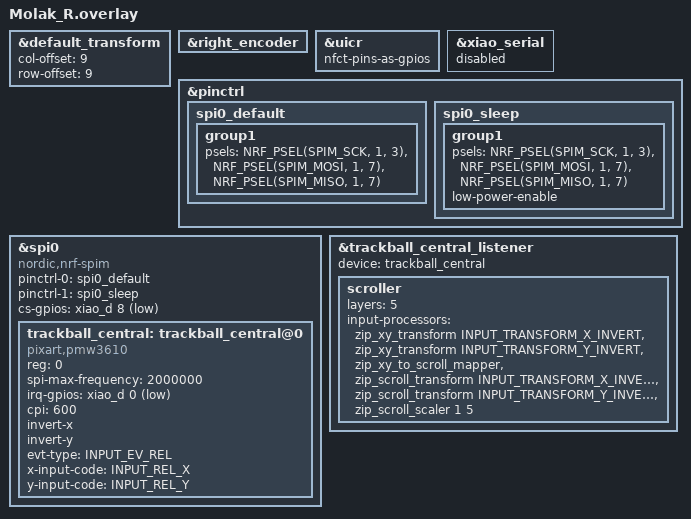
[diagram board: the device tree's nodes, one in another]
#include "Molak.dtsi"
#include <input/processors.dtsi>
#include <zephyr/dt-bindings/input/input-event-codes.h>

&default_transform {
    col-offset = <9>;
    row-offset = <9>;
};

&right_encoder {
    status = "okay";
};

&uicr {
    nfct-pins-as-gpios;
};

&xiao_serial {
    status = "disabled";
};

&pinctrl {
    spi0_default: spi0_default {
        group1 {
            psels = <NRF_PSEL(SPIM_SCK, 1, 3)>,
                <NRF_PSEL(SPIM_MOSI, 1, 7)>,
                <NRF_PSEL(SPIM_MISO, 1, 7)>;
        };
    };

    spi0_sleep: spi0_sleep {
        group1 {
            psels = <NRF_PSEL(SPIM_SCK, 1, 3)>,
                <NRF_PSEL(SPIM_MOSI, 1, 7)>,
                <NRF_PSEL(SPIM_MISO, 1, 7)>;
            low-power-enable;
        };
    };
};

&spi0 {
    status = "okay";
    compatible = "nordic,nrf-spim";
    pinctrl-0 = <&spi0_default>;
    pinctrl-1 = <&spi0_sleep>;
    pinctrl-names = "default", "sleep";
    cs-gpios = <&xiao_d 8 GPIO_ACTIVE_LOW>; // set cs

    trackball_central: trackball_central@0 {
        status = "okay";
        compatible = "pixart,pmw3610";
        reg = <0>;
        spi-max-frequency = <2000000>;
        irq-gpios = <&xiao_d 0 (GPIO_ACTIVE_LOW | GPIO_PULL_UP)>; // set motion
        cpi = <600>;
        // swap-xy;
        invert-x;
        invert-y;
        evt-type = <INPUT_EV_REL>;
        x-input-code = <INPUT_REL_X>;
        y-input-code = <INPUT_REL_Y>;
    };
};

&trackball_central_listener {
    status = "okay";
    device = <&trackball_central>;
    scroller {
        layers = <5>;  // configure enable layer
        input-processors = 
            // <&zip_xy_transform INPUT_TRANSFORM_XY_SWAP>,     //swap x and y
            <&zip_xy_transform INPUT_TRANSFORM_X_INVERT>,       //invert x
            <&zip_xy_transform INPUT_TRANSFORM_Y_INVERT>,       //invert y
            <&zip_xy_to_scroll_mapper>,                         //change mode to scroll
            <&zip_scroll_transform INPUT_TRANSFORM_X_INVERT>,   //invert x when scroll
            <&zip_scroll_transform INPUT_TRANSFORM_Y_INVERT>,   //invert y when scroll
            <&zip_scroll_scaler 1 5>;                           //set scroll scale
    };
};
